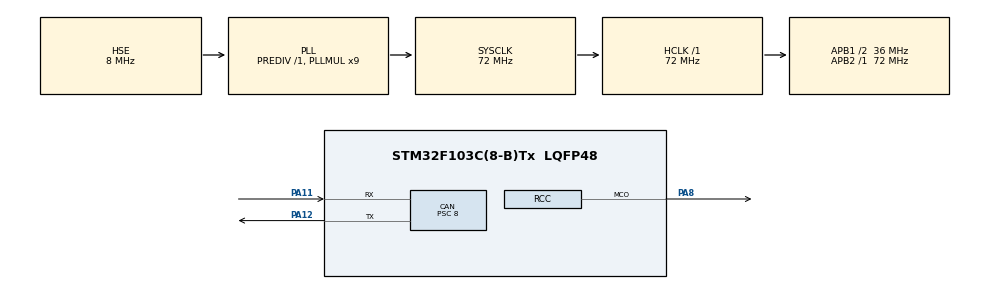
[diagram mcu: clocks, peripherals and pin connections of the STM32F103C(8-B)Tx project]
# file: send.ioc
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Mcu.Family=STM32F1
RCC.PLLSourceVirtual=RCC_PLLSOURCE_HSE
PD1-OSC_OUT.Mode=HSE-External-Oscillator
CAN.ABOM=ENABLE
CAN.CalculateBaudRate=500000
PA11.Mode=CAN_Activate
PD0-OSC_IN.Signal=RCC_OSC_IN
RCC.APB1CLKDivider=RCC_HCLK_DIV2
CAN.CalculateTimeBit=1999.99
RCC.SYSCLKSource=RCC_SYSCLKSOURCE_PLLCLK
ProjectManager.StackSize=0x400
PD1-OSC_OUT.Signal=RCC_OSC_OUT
PA13.Signal=SYS_JTMS-SWDIO
PA12.Signal=CAN_TX
CAN.BS2=CAN_BS2_4TQ
CAN.Prescaler=8
CAN.BS1=CAN_BS1_4TQ
ProjectManager.TargetToolchain=STM32CubeIDE
RCC.HCLKFreq_Value=72000000
RCC.APB2TimFreq_Value=72000000
RCC.USBFreq_Value=72000000
CAN.Mode=CAN_MODE_LOOPBACK
RCC.AHBFreq_Value=72000000
PD0-OSC_IN.Mode=HSE-External-Oscillator
board=custom
RCC.PLLMUL=RCC_PLL_MUL9
RCC.APB2Freq_Value=72000000
PA14.Mode=Serial_Wire
NVIC.USB_LP_CAN1_RX0_IRQn=true\:0\:0\:false\:false\:true\:true\:true
RCC.RCC_MCOSource=RCC_MCO1SOURCE_HSE
PA8.Signal=RCC_MCO
PA13.Mode=Serial_Wire
Mcu.Name=STM32F103C(8-B)Tx
CAN.CalculateTimeQuantum=222.22222222222223
RCC.SYSCLKFreq_VALUE=72000000
Mcu.Package=LQFP48
PA12.Mode=CAN_Activate
PA11.Signal=CAN_RX
PA14.Signal=SYS_JTCK-SWCLK
ProjectManager.HeapSize=0x200
NVIC.PriorityGroup=NVIC_PRIORITYGROUP_4
RCC.APB1TimFreq_Value=72000000
PA8.Mode=Clock-out
CAN.AWUM=ENABLE
RCC.APB1Freq_Value=36000000

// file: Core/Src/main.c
/* USER CODE BEGIN Header */
/**
  ******************************************************************************
  * @file           : main.c
  * @brief          : Main program body
  ******************************************************************************
  * @attention
  *
  * <h2><center>&copy; Copyright (c) 2021 STMicroelectronics.
  * All rights reserved.</center></h2>
  *
  * This software component is licensed by ST under BSD 3-Clause license,
  * the "License"; You may not use this file except in compliance with the
  * License. You may obtain a copy of the License at:
  *                        opensource.org/licenses/BSD-3-Clause
  *
  ******************************************************************************
  */
/* USER CODE END Header */
#include "main.h"
#include "can.h"
#include "gpio.h"

/* USER CODE BEGIN Includes */
#include "CanSent.h"
/* USER CODE END Includes */

#pragma clang diagnostic push
#pragma ide diagnostic ignored "EndlessLoop"
/* USER CODE BEGIN PTD */
CAN_RxHeaderTypeDef   RxHeader;
CAN_HandleTypeDef     CanHandle;
/* USER CODE END PTD */

/* USER CODE BEGIN PV */
uint8_t               TxData[8];
uint8_t               RxData[8];
uint32_t              TxMailbox;

/* USER CODE END PV */

void SystemClock_Config(void);

int main(void)
{

  /* MCU Configuration--------------------------------------------------------*/

  /* Reset of all peripherals, Initializes the Flash interface and the Systick. */
  HAL_Init();

  /* Configure the system clock */
  SystemClock_Config();

  /* Initialize all configured peripherals */
  MX_GPIO_Init();
  MX_CAN_Init();
  /* USER CODE BEGIN 2 */
    CAN_Filter_Config();
    TxData[0]=0xff;
    HAL_CAN_ActivateNotification(&CanHandle, CAN_IT_RX_FIFO0_MSG_PENDING);
  /* USER CODE END 2 */

  /* Infinite loop */
  while (1)
  {
      HAL_CAN_AddTxMessage(&CanHandle, &Can_TxHeader, TxData, &TxMailbox);
      HAL_Delay(1000);
  }
}

void SystemClock_Config(void)
{
  RCC_OscInitTypeDef RCC_OscInitStruct = {0};
  RCC_ClkInitTypeDef RCC_ClkInitStruct = {0};

  /** Initializes the RCC Oscillators according to the specified parameters
  * in the RCC_OscInitTypeDef structure.
  */
  RCC_OscInitStruct.OscillatorType = RCC_OSCILLATORTYPE_HSE;
  RCC_OscInitStruct.HSEState = RCC_HSE_ON;
  RCC_OscInitStruct.HSEPredivValue = RCC_HSE_PREDIV_DIV1;
  RCC_OscInitStruct.HSIState = RCC_HSI_ON;
  RCC_OscInitStruct.PLL.PLLState = RCC_PLL_ON;
  RCC_OscInitStruct.PLL.PLLSource = RCC_PLLSOURCE_HSE;
  RCC_OscInitStruct.PLL.PLLMUL = RCC_PLL_MUL9;
  if (HAL_RCC_OscConfig(&RCC_OscInitStruct) != HAL_OK)
  {
    Error_Handler();
  }
  /** Initializes the CPU, AHB and APB buses clocks
  */
  RCC_ClkInitStruct.ClockType = RCC_CLOCKTYPE_HCLK|RCC_CLOCKTYPE_SYSCLK
                              |RCC_CLOCKTYPE_PCLK1|RCC_CLOCKTYPE_PCLK2;
  RCC_ClkInitStruct.SYSCLKSource = RCC_SYSCLKSOURCE_PLLCLK;
  RCC_ClkInitStruct.AHBCLKDivider = RCC_SYSCLK_DIV1;
  RCC_ClkInitStruct.APB1CLKDivider = RCC_HCLK_DIV2;
  RCC_ClkInitStruct.APB2CLKDivider = RCC_HCLK_DIV1;

  if (HAL_RCC_ClockConfig(&RCC_ClkInitStruct, FLASH_LATENCY_2) != HAL_OK)
  {
    Error_Handler();
  }
  HAL_RCC_MCOConfig(RCC_MCO, RCC_MCO1SOURCE_HSE, RCC_MCODIV_1);
}

void Error_Handler(void)
{
  __disable_irq();
  while (1)
  {
  }
}
void HAL_CAN_RxFifo0MsgPendingCallback(CAN_HandleTypeDef *CanHandle)
{
    /* Get RX message */
    if (HAL_CAN_GetRxMessage(CanHandle, CAN_RX_FIFO0, &RxHeader, RxData) != HAL_OK)
    {
        /* Reception Error */
        Error_Handler();
    }

        uint8_t a= RxData[0];

}

/************************ (C) COPYRIGHT STMicroelectronics *****END OF FILE****/

#pragma clang diagnostic pop
